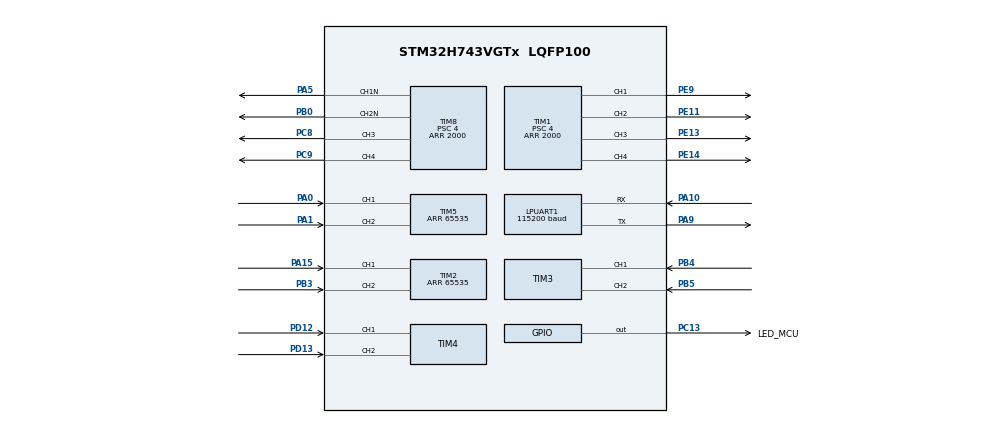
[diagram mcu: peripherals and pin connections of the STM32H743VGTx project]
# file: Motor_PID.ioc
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CORTEX_M7.default_mode_Activation=1
LPUART1.BaudRate=115200
Mcu.Family=STM32H7
Mcu.Name=STM32H743VGTx
Mcu.Package=LQFP100
NVIC.PriorityGroup=NVIC_PRIORITYGROUP_4
PA0.Signal=S_TIM5_CH1
PA1.Signal=S_TIM5_CH2
PA10.Mode=Asynchronous
PA10.Signal=LPUART1_RX
PA13\ (JTMS/SWDIO).Mode=Serial_Wire
PA13\ (JTMS/SWDIO).Signal=DEBUG_JTMS-SWDIO
PA14\ (JTCK/SWCLK).Mode=Serial_Wire
PA14\ (JTCK/SWCLK).Signal=DEBUG_JTCK-SWCLK
PA15\ (JTDI).Signal=S_TIM2_CH1_ETR
PA5.Mode=PWM Generation1 CH1N
PA5.Signal=TIM8_CH1N
PA9.Mode=Asynchronous
PA9.Signal=LPUART1_TX
PB0.Mode=PWM Generation2 CH2N
PB0.Signal=TIM8_CH2N
PB3\ (JTDO/TRACESWO).Signal=S_TIM2_CH2
PB4\ (NJTRST).Signal=S_TIM3_CH1
PB5.Signal=S_TIM3_CH2
PC13.GPIO_Label=LED_MCU
PC13.Signal=GPIO_Output
PC8.Signal=S_TIM8_CH3
PC9.Signal=S_TIM8_CH4
PD12.Signal=S_TIM4_CH1
PD13.Signal=S_TIM4_CH2
PE11.Signal=S_TIM1_CH2
PE13.Signal=S_TIM1_CH3
PE14.Signal=S_TIM1_CH4
PE9.Signal=S_TIM1_CH1
PH0-OSC_IN\ (PH0).Mode=HSE-External-Oscillator
PH0-OSC_IN\ (PH0).Signal=RCC_OSC_IN
PH1-OSC_OUT\ (PH1).Mode=HSE-External-Oscillator
PH1-OSC_OUT\ (PH1).Signal=RCC_OSC_OUT
ProjectManager.HeapSize=0x200
ProjectManager.StackSize=0x400
ProjectManager.TargetToolchain=STM32CubeIDE
RCC.ADCFreq_Value=50390625
RCC.APB1Freq_Value=120000000
RCC.APB2Freq_Value=120000000
RCC.APB3Freq_Value=120000000
RCC.APB4Freq_Value=120000000
RCC.CortexFreq_Value=480000000
RCC.D1PPRE=RCC_APB3_DIV2
RCC.D2PPRE1=RCC_APB1_DIV2
RCC.D2PPRE2=RCC_APB2_DIV2
RCC.D3PPRE=RCC_APB4_DIV2
RCC.DIVM1=5
RCC.DIVN1=192
RCC.DIVQ1=5
RCC.HCLKFreq_Value=240000000
RCC.HPRE=RCC_HCLK_DIV2
RCC.PLLFRACN=0
RCC.PLLSourceVirtual=RCC_PLLSOURCE_HSE
RCC.SYSCLKFreq_VALUE=480000000
RCC.SYSCLKSource=RCC_SYSCLKSOURCE_PLLCLK
RCC.USBFreq_Value=192000000
SH.S_TIM1_CH1.0=TIM1_CH1,PWM Generation1 CH1
SH.S_TIM1_CH2.0=TIM1_CH2,PWM Generation2 CH2
SH.S_TIM1_CH3.0=TIM1_CH3,PWM Generation3 CH3
SH.S_TIM1_CH4.0=TIM1_CH4,PWM Generation4 CH4
SH.S_TIM2_CH1_ETR.0=TIM2_CH1,Encoder_Interface
SH.S_TIM2_CH2.0=TIM2_CH2,Encoder_Interface
SH.S_TIM3_CH1.0=TIM3_CH1,Encoder_Interface
SH.S_TIM3_CH2.0=TIM3_CH2,Encoder_Interface
SH.S_TIM4_CH1.0=TIM4_CH1,Encoder_Interface
SH.S_TIM4_CH2.0=TIM4_CH2,Encoder_Interface
SH.S_TIM5_CH1.0=TIM5_CH1,Encoder_Interface
SH.S_TIM5_CH2.0=TIM5_CH2,Encoder_Interface
SH.S_TIM8_CH3.0=TIM8_CH3,PWM Generation3 CH3
SH.S_TIM8_CH4.0=TIM8_CH4,PWM Generation4 CH4
TIM1.AutoReloadPreload=TIM_AUTORELOAD_PRELOAD_ENABLE
TIM1.Channel-PWM\ Generation1\ CH1=TIM_CHANNEL_1
TIM1.Channel-PWM\ Generation2\ CH2=TIM_CHANNEL_2
TIM1.Channel-PWM\ Generation3\ CH3=TIM_CHANNEL_3
TIM1.Channel-PWM\ Generation4\ CH4=TIM_CHANNEL_4
TIM1.Period=2000
TIM1.Prescaler=4
TIM2.EncoderMode=TIM_ENCODERMODE_TI12
TIM2.Period=65535
TIM3.EncoderMode=TIM_ENCODERMODE_TI12
TIM4.EncoderMode=TIM_ENCODERMODE_TI12
TIM5.EncoderMode=TIM_ENCODERMODE_TI12
TIM5.Period=65535
TIM8.AutoReloadPreload=TIM_AUTORELOAD_PRELOAD_ENABLE
TIM8.Channel-PWM\ Generation1\ CH1N=TIM_CHANNEL_1
TIM8.Channel-PWM\ Generation2\ CH2N=TIM_CHANNEL_2
TIM8.Channel-PWM\ Generation3\ CH3=TIM_CHANNEL_3
TIM8.Channel-PWM\ Generation4\ CH4=TIM_CHANNEL_4
TIM8.Period=2000
TIM8.Prescaler=4
VP_MEMORYMAP_VS_MEMORYMAP.Mode=CurAppReg
board=custom

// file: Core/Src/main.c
/* USER CODE BEGIN Header */
/**
  ******************************************************************************
  * @file           : main.c
  * @brief          : Main program body
  ******************************************************************************
  * @attention
  *
  * Copyright (c) 2024 STMicroelectronics.
  * All rights reserved.
  *
  * This software is licensed under terms that can be found in the LICENSE file
  * in the root directory of this software component.
  * If no LICENSE file comes with this software, it is provided AS-IS.
  *
  ******************************************************************************
  */
/* USER CODE END Header */
#include "main.h"
#include "usart.h"
#include "memorymap.h"
#include "tim.h"
#include "gpio.h"

/* USER CODE BEGIN Includes */
#include "app.h"
/* USER CODE END Includes */

void SystemClock_Config(void);
static void MPU_Config(void);

int main(void)
{

  /* MPU Configuration--------------------------------------------------------*/
  MPU_Config();

  /* MCU Configuration--------------------------------------------------------*/

  /* Reset of all peripherals, Initializes the Flash interface and the Systick. */
  HAL_Init();

  /* Configure the system clock */
  SystemClock_Config();

  /* Initialize all configured peripherals */
  MX_GPIO_Init();
  MX_TIM2_Init();
  MX_TIM3_Init();
  MX_TIM4_Init();
  MX_TIM5_Init();
  MX_TIM1_Init();
  MX_TIM8_Init();
  MX_LPUART1_UART_Init();
  /* USER CODE BEGIN 2 */
  App_Handle();
  /* USER CODE END 2 */

  /* Infinite loop */
  while (1)
  {

  }
}

void SystemClock_Config(void)
{
  RCC_OscInitTypeDef RCC_OscInitStruct = {0};
  RCC_ClkInitTypeDef RCC_ClkInitStruct = {0};

  /** Supply configuration update enable
  */
  HAL_PWREx_ConfigSupply(PWR_LDO_SUPPLY);

  /** Configure the main internal regulator output voltage
  */
  __HAL_PWR_VOLTAGESCALING_CONFIG(PWR_REGULATOR_VOLTAGE_SCALE1);

  while(!__HAL_PWR_GET_FLAG(PWR_FLAG_VOSRDY)) {}

  __HAL_RCC_SYSCFG_CLK_ENABLE();
  __HAL_PWR_VOLTAGESCALING_CONFIG(PWR_REGULATOR_VOLTAGE_SCALE0);

  while(!__HAL_PWR_GET_FLAG(PWR_FLAG_VOSRDY)) {}

  /** Initializes the RCC Oscillators according to the specified parameters
  * in the RCC_OscInitTypeDef structure.
  */
  RCC_OscInitStruct.OscillatorType = RCC_OSCILLATORTYPE_HSE;
  RCC_OscInitStruct.HSEState = RCC_HSE_ON;
  RCC_OscInitStruct.PLL.PLLState = RCC_PLL_ON;
  RCC_OscInitStruct.PLL.PLLSource = RCC_PLLSOURCE_HSE;
  RCC_OscInitStruct.PLL.PLLM = 5;
  RCC_OscInitStruct.PLL.PLLN = 192;
  RCC_OscInitStruct.PLL.PLLP = 2;
  RCC_OscInitStruct.PLL.PLLQ = 5;
  RCC_OscInitStruct.PLL.PLLR = 2;
  RCC_OscInitStruct.PLL.PLLRGE = RCC_PLL1VCIRANGE_2;
  RCC_OscInitStruct.PLL.PLLVCOSEL = RCC_PLL1VCOWIDE;
  RCC_OscInitStruct.PLL.PLLFRACN = 0;
  if (HAL_RCC_OscConfig(&RCC_OscInitStruct) != HAL_OK)
  {
    Error_Handler();
  }

  /** Initializes the CPU, AHB and APB buses clocks
  */
  RCC_ClkInitStruct.ClockType = RCC_CLOCKTYPE_HCLK|RCC_CLOCKTYPE_SYSCLK
                              |RCC_CLOCKTYPE_PCLK1|RCC_CLOCKTYPE_PCLK2
                              |RCC_CLOCKTYPE_D3PCLK1|RCC_CLOCKTYPE_D1PCLK1;
  RCC_ClkInitStruct.SYSCLKSource = RCC_SYSCLKSOURCE_PLLCLK;
  RCC_ClkInitStruct.SYSCLKDivider = RCC_SYSCLK_DIV1;
  RCC_ClkInitStruct.AHBCLKDivider = RCC_HCLK_DIV2;
  RCC_ClkInitStruct.APB3CLKDivider = RCC_APB3_DIV2;
  RCC_ClkInitStruct.APB1CLKDivider = RCC_APB1_DIV2;
  RCC_ClkInitStruct.APB2CLKDivider = RCC_APB2_DIV2;
  RCC_ClkInitStruct.APB4CLKDivider = RCC_APB4_DIV2;

  if (HAL_RCC_ClockConfig(&RCC_ClkInitStruct, FLASH_LATENCY_4) != HAL_OK)
  {
    Error_Handler();
  }
}

/* USER CODE BEGIN 4 */
#ifdef __GNUC__
#define PUTCHAR_PROTOTYPE int __io_putchar(int ch)
#else
#define PUTCHAR_PROTOTYPE int fputc(int ch, FILE *f)
#endif /* __GNUC__ */
PUTCHAR_PROTOTYPE
{
    /* Place your implementation of fputc here */
    /* e.g. write a character to the EVAL_COM1 and Loop until the end of transmission */
    HAL_UART_Transmit(&hlpuart1, (uint8_t *)&ch, 1, 0xFFFF);
    return ch;
}
/* USER CODE END 4 */

 /* MPU Configuration */

void MPU_Config(void)
{
  MPU_Region_InitTypeDef MPU_InitStruct = {0};

  /* Disables the MPU */
  HAL_MPU_Disable();

  /** Initializes and configures the Region and the memory to be protected
  */
  MPU_InitStruct.Enable = MPU_REGION_ENABLE;
  MPU_InitStruct.Number = MPU_REGION_NUMBER0;
  MPU_InitStruct.BaseAddress = 0x0;
  MPU_InitStruct.Size = MPU_REGION_SIZE_4GB;
  MPU_InitStruct.SubRegionDisable = 0x87;
  MPU_InitStruct.TypeExtField = MPU_TEX_LEVEL0;
  MPU_InitStruct.AccessPermission = MPU_REGION_NO_ACCESS;
  MPU_InitStruct.DisableExec = MPU_INSTRUCTION_ACCESS_DISABLE;
  MPU_InitStruct.IsShareable = MPU_ACCESS_SHAREABLE;
  MPU_InitStruct.IsCacheable = MPU_ACCESS_NOT_CACHEABLE;
  MPU_InitStruct.IsBufferable = MPU_ACCESS_NOT_BUFFERABLE;

  HAL_MPU_ConfigRegion(&MPU_InitStruct);
  /* Enables the MPU */
  HAL_MPU_Enable(MPU_PRIVILEGED_DEFAULT);

}

void Error_Handler(void)
{
  __disable_irq();
  while (1)
  {
  }
}
